# AT32F437 register map
Vendor: Keil; Series: AT32F437; File version: 1.0
CPU: CM4 r0p1, little endian, no MPU, FPU, 4 interrupt priority bits
Registers are 32-bit, read-write, reset 0x0 unless marked. A register's access mark holds for its fields unless they carry their own. Offsets are from the block's base; [hi:lo] are bit positions.

## ETHERNET_MMC — Ethernet: MAC management counters
Base 0x40028100
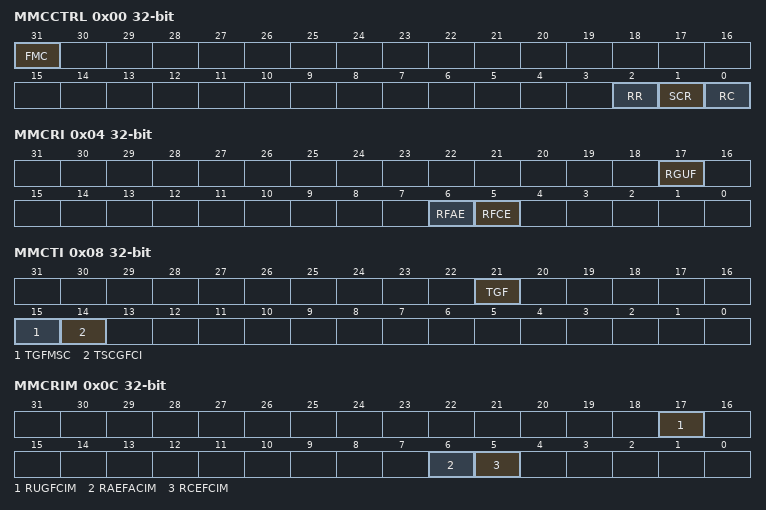
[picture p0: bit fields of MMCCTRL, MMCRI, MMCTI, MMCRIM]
0x00 MMCCTRL — Ethernet MMC control register
  [31] FMC — Freeze MMC counter
  [2] RR — Reset on read
  [1] SCR — Stop counter rollover
  [0] RC — Reset counter
0x04 MMCRI — Ethernet MMC receive interrupt register
  [17] RGUF — Received good unicast frames
  [6] RFAE — Received frames alignment error
  [5] RFCE — Received frames CRC error
0x08 MMCTI — Ethernet MMC transmit interrupt register
  [21] TGF — Transmitted good frames
  [15] TGFMSC — Transmit good frames more single collision
  [14] TSCGFCI — Transmit single collision good frame counter interrupt
0x0C MMCRIM — Ethernet MMC receive interrupt mask register
  [17] RUGFCIM — Received unicast good frame counter interrupt mask
  [6] RAEFACIM — Received alignment error frame alignment counter interrupt mask
  [5] RCEFCIM — Received CRC error frame counter interrupt mask
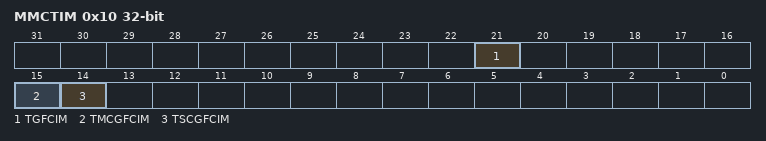
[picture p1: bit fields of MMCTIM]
0x10 MMCTIM — Ethernet MMC transmit interrupt mask register
  [21] TGFCIM — Transmitted good frame counter interrupt mask
  [15] TMCGFCIM — Transmit multiple collision good frame counter interrupt mask
  [14] TSCGFCIM — Transmit single collision good frame counter interrupt mask
0x4C MMCTFSCC ro — Ethernet MMC transmitted good frames after a single collision counter
  [31:0] TGFSCC — Transmitted good frames single collision counter
0x50 MMCTFMSCC ro — Ethernet MMC transmitted good frames after more than a single collision
  [31:0] TGFMSCC — Transmitted good frame more single collision counter
0x68 MMCTFCNT ro — Ethernet MMC transmitted good frames counter register
  [31:0] TGFC — Transmitted good frames counter
0x94 MMCRFCECNT ro — Ethernet MMC received frames with CRC error counter register
  [31:0] RFCEC — Received frames CRC error counter
0x98 MMCRFAECNT ro — Ethernet MMC received frames with alignment error counter register
  [31:0] RFAEC — Received frames alignment error counter
0xC4 MMCRGUFCNT ro — MMC received good unicast frames counter register
  [31:0] RGUFC — Received good unicast frames counter

## ETHERNET_PTP — Ethernet: Precision time protocol
Base 0x40028700
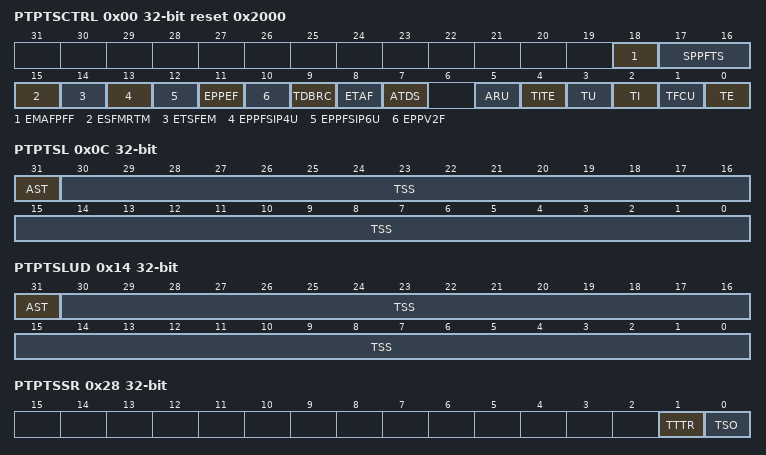
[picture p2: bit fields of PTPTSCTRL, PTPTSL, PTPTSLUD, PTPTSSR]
0x00 PTPTSCTRL reset 0x2000 — Ethernet PTP time stamp control register
  [18] EMAFPFF — Enable MAC address for PTP frame filtering
  [17:16] SPPFTS — Select PTP packet for taking snapshot
  [15] ESFMRTM — Enable snapshot for message relevant to master
  [14] ETSFEM — Enable timestamp snapshot for event message
  [13] EPPFSIP4U — Enable processing of PTP frames sent over IPv4-UDP
  [12] EPPFSIP6U — Enable processing of PTP frames sent over IPv6-UDP
  [11] EPPEF — Enable processing of PTP over EMAC frames
  [10] EPPV2F — Enable PTP packet processing for version2 format
  [9] TDBRC — Timestamp digital or binary rollover control
  [8] ETAF — Enable timestamp for all frames
  [7] ATDS — Alternate dma descriptor size
  [5] ARU — Addend register update
  [4] TITE — Timestamp interrupt trigger enable
  [3] TU — Timestamp update
  [2] TI — Timestamp initialize
  [1] TFCU — Timestamp fine or coarse update
  [0] TE — Timestamp enable
0x04 PTPSSINC — Ethernet PTP subsecond increment register
  [7:0] SSIV — Sub-second increment value
0x08 PTPTSH ro — Ethernet PTP time stamp high register
  [31:0] TS — Timestamp second
0x0C PTPTSL ro — Ethernet PTP time stamp low register
  [31] AST — Add or subtract time
  [30:0] TSS — Timestamp subseconds
0x10 PTPTSHUD — Ethernet PTP time stamp high update register
  [31:0] TS — Timestamp second
0x14 PTPTSLUD — Ethernet PTP time stamp low update register
  [31] AST — Add or subtract time
  [30:0] TSS — Timestamp subseconds
0x18 PTPTSAD — Ethernet PTP time stamp addend register
  [31:0] TAR — Timestamp addend register
0x1C PTPTTH — Ethernet PTP target time high register
  [31:0] TTSR — Target time seconds register
0x20 PTPTTL — Ethernet PTP target time low register
  [31:0] TTLR — Target timestamp low register
0x28 PTPTSSR ro — Ethernet PTP time stamp status register
  [1] TTTR — Timestamp target time reached
  [0] TSO — Timestamp second overflow
0x2C PTPPPSCR ro — Ethernet PTP PPS control register
  [3:0] POFC — PPS Output frequency control

## FPU — Floting point unit
Base 0xE000EF34
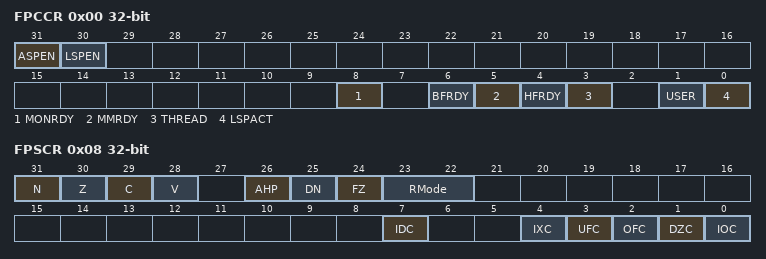
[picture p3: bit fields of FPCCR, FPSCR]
0x00 FPCCR — Floating-point context control register
  [31] ASPEN, [30] LSPEN, [8] MONRDY, [6] BFRDY, [5] MMRDY, [4] HFRDY, [3] THREAD, [1] USER, [0] LSPACT
0x04 FPCAR — Floating-point context address register
  [31:3] ADDRESS — Location of unpopulated floating-point
0x08 FPSCR — Floating-point status control register
  [31] N — Negative condition code flag
  [30] Z — Zero condition code flag
  [29] C — Carry condition code flag
  [28] V — Overflow condition code flag
  [26] AHP — Alternative half-precision control bit
  [25] DN — Default NaN mode control bit
  [24] FZ — Flush-to-zero mode control bit:
  [23:22] RMode — Rounding Mode control field
  [7] IDC — Input denormal cumulative exception bit.
  [4] IXC — Inexact cumulative exception bit
  [3] UFC — Underflow cumulative exception bit
  [2] OFC — Overflow cumulative exception bit
  [1] DZC — Division by zero cumulative exception bit.
  [0] IOC — Invalid operation cumulative exception bit
